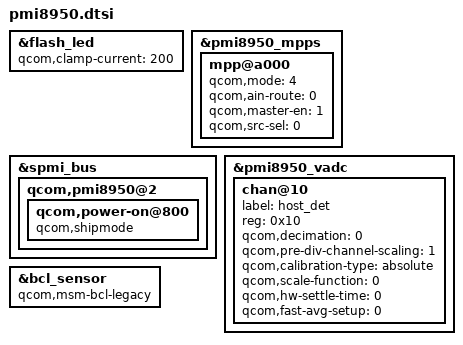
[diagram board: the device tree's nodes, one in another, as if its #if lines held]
&flash_led {
	/delete-property/ qcom,clamp-curr;
	qcom,clamp-current = <200>;
};

&pmi8950_mpps {
	mpp@a000 {
		/* Host detect */
		status = "ok";
		qcom,mode = <4>; /* AIN input */
		qcom,ain-route = <0>; /* AMUX 5 */
		qcom,master-en = <1>;
		qcom,src-sel = <0>; /* Function constant */
	};
};

&spmi_bus {
	qcom,pmi8950@2 {
		qcom,power-on@800 {
			qcom,shipmode;
		};
	};
};

&pmi8950_vadc {
	chan@10 {
		label = "host_det";
		reg = <0x10>;
		qcom,decimation = <0>;
		qcom,pre-div-channel-scaling = <1>;
		qcom,calibration-type = "absolute";
		qcom,scale-function = <0>;
		qcom,hw-settle-time = <0>;
		qcom,fast-avg-setup = <0>;
	};
};

#ifdef CONFIG_MSM_BCL_PERIPHERAL_CTL_LEGACY
&bcl_sensor {
	compatible = "qcom,msm-bcl-legacy";
};
#endif
